# DA1470x register map
Vendor: Dialog; Series: DA1470x; File version: 1.2
CPU: CM33 r0p2, little endian, MPU, FPU, DSP, VTOR, 4 interrupt priority bits
Registers are 32-bit, read-write, reset 0x0 unless marked. A register's access mark holds for its fields unless they carry their own. Offsets are from the block's base; [hi:lo] are bit positions.

## EMMC (part 2 of 3) — EMMC registers
Base 0x30058000
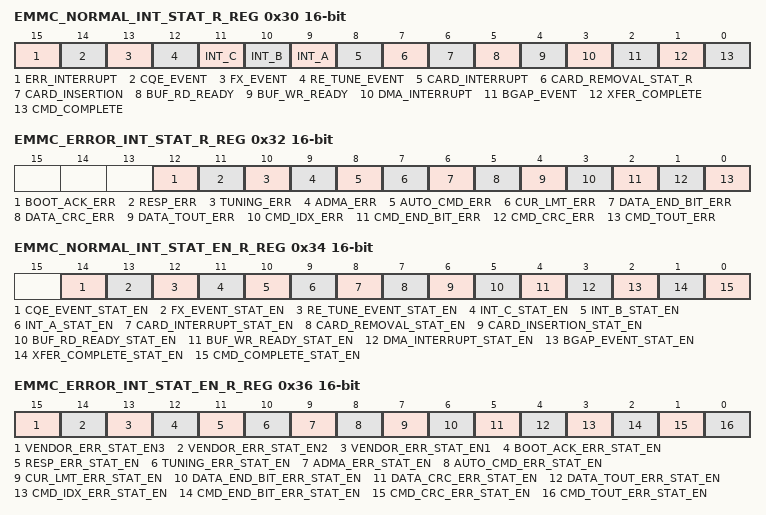
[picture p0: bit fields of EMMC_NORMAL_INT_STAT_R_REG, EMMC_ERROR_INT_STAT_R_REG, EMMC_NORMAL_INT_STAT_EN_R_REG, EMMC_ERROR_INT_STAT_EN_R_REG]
0x30 EMMC_NORMAL_INT_STAT_R_REG 16-bit — This register reflects the status of the Normal Interrupt. This register is applicable for an SD/eMMC/UHS-II mode.
  [15] ERR_INTERRUPT ro — Error Interrupt. If any of the bits in the Error Interrupt Status register are set, then this bit is set. Values: 0x0 (FALSE): No Error 0x1 (TRUE): Error
  [14] CQE_EVENT — Command Queuing Event This status is set if Command Queuing/Crypto related event has occurred in eMMC/SD mode. Read CQHCI's CQIS/CRNQIS register for more details. Values: 0x0 (FALSE): No Event 0x1 (TRUE): Command Queuing Event is detected
  [13] FX_EVENT ro — FX Event. This status is set when R[14] of response register is set to 1 and Response Type R1/R5 is set to 0 in Transfer Mode register. This interrupt is used with response check function. Values: 0x0 (FALSE): No Event 0x1 (TRUE): FX Event is detected
  [12] RE_TUNE_EVENT ro — Re-tuning Event. This bit is set if the Re-Tuning Request changes from 0 to 1. Re-Tuning request is not supported.
  [11] INT_C ro — INT_C (Embedded). This bit is set if INT_C is enabled and if INT_C# pin is in low level. The INT_C# pin is not supported.
  [10] INT_B ro — INT_B (Embedded). This bit is set if INT_B is enabled and if INT_B# pin is in low level. The INT_B# pin is not supported.
  [9] INT_A ro — INT_A (Embedded). This bit is set if INT_A is enabled and if INT_A# pin is in low level. The INT_A# pin is not supported.
  [8] CARD_INTERRUPT ro — Card Interrupt. This bit reflects the synchronized value of: - DAT[1] Interrupt Input for SD Mode - DAT[2] Interrupt Input for UHS-II Mode Values: 0x0 (FALSE): No Card Interrupt 0x1 (TRUE): Generate Card Interrupt
  [7] CARD_REMOVAL_STAT_R — Card Removal. This bit is set if the Card Inserted in the Present State register changes from 1 to 0. Values: 0x0 (FALSE): Card state stable or Debouncing 0x1 (TRUE): Card Removed
  [6] CARD_INSERTION — Card Insertion This bit is set if the Card Inserted in the Present State register changes from 0 to 1. Values: 0x0 (FALSE): Card state stable or Debouncing 0x1 (TRUE): Card Inserted
  [5] BUF_RD_READY — Buffer Read Ready. This bit is set if the Buffer Read Enable changes from 0 to 1. Values: 0x0 (FALSE): Not ready to read buffer 0x1 (TRUE): Ready to read buffer
  [4] BUF_WR_READY — Buffer Write Ready. This bit is set if the Buffer Write Enable changes from 0 to 1. Values: 0x0 (FALSE): Not ready to write buffer 0x1 (TRUE): Ready to write buffer
  [3] DMA_INTERRUPT — DMA Interrupt. This bit is set if the Host Controller detects the SDMA Buffer Boundary during transfer. In case of ADMA, by setting the Int field in the descriptor table, the Host controller generates this interrupt. This interrupt is not generated after a Transfer Complete. Values: 0x0 (FALSE): No DMA Interrupt 0x1 (TRUE): DMA Interrupt is generated
  [2] BGAP_EVENT — Block Gap Event. This bit is set when both read/write transaction is stopped at block gap due to a Stop at Block Gap Request. Values: 0x0 (FALSE): No Block Gap Event 0x1 (TRUE): Transaction stopped at block gap
  [1] XFER_COMPLETE — Transfer Complete. This bit is set when a read/write transfer and a command with status busy is completed. Values: 0x0 (FALSE): Not complete 0x1 (TRUE): Command execution is completed
  [0] CMD_COMPLETE — Command Complete. In an SD/eMMC Mode, this bit is set when the end bit of a response except for Auto CMD12 and Auto CMD23. This interrupt is not generated when the Response Interrupt Disable in Transfer Mode Register is set to 1. Values: 0x0 (FALSE): No command complete 0x1 (TRUE): Command Complete
0x32 EMMC_ERROR_INT_STAT_R_REG 16-bit — This register enables an interrupt when the Error Interrupt Status Enable is enabled and at least one of the statuses is set to
  [12] BOOT_ACK_ERR — Boot Acknowledgement Error. This bit is set when there is a timeout for boot acknowledgement or when detecting boot ack status having a value other than 010. This is applicable only when boot acknowledgement is expected in eMMC mode. Values: 0x0 (FALSE): No error 0x1 (TRUE): Error
  [11] RESP_ERR — Response Error. Host Controller Version 4.00 supports response error check function to avoid overhead of response error check by Host Driver during DMA execution. If Response Error Check Enable is set to 1 in the Transfer Mode register, Host Controller Checks R1 or R5 response. If an error is detected in a response, this bit is set to 1.This is applicable in SD/eMMC mode. Values: 0x0 (FALSE): No error 0x1 (TRUE): Error
  [10] TUNING_ERR — Tuning Error. This bit is set when an unrecoverable error is detected in a tuning circuit except during the tuning procedure (occurrence of an error during tuning procedure is indicated by Sampling Clock Select in the Host Control 2 register). By detecting Tuning Error, Host Driver needs to abort a command executing and perform tuning. To reset tuning circuit, Sampling Clock Select is set to 0 before executing tuning procedure. The Tuning Error is higher priority than the other error interrupts generated during data transfer. By detecting Tuning Error, the Host Driver must discard data transferred by a current read/write command and retry data transfer after the Host Controller retrieved from the tuning circuit error. This is applicable in SD/eMMC mode. Values: 0x0 (FALSE): No error 0x1 (TRUE): Error
  [9] ADMA_ERR — ADMA Error. This bit is set when the Host Controller detects error during ADMA-based data transfer. The error could be due to following reasons: - Error response received from System bus (Master I/F) - ADMA3,ADMA2 Descriptors invalid - CQE Task or Transfer descriptors invalid When the error occurs, the state of the ADMA is saved in the ADMA Error Status register. In eMMC CQE mode: The Host Controller generates this Interrupt when it detects an invalid descriptor data (Valid=0) at the ST_FDS state. ADMA Error State in the ADMA Error Status indicates that an error has occurred in ST_FDS state. The Host Driver may find that Valid bit is not set at the error descriptor. Values: 0x0 (FALSE): No error 0x1 (TRUE): Error
  [8] AUTO_CMD_ERR — Auto CMD Error. This error status is used by Auto CMD12 and Auto CMD23 in SD/eMMC mode. This bit is set when detecting that any of the bits D00 to D05 in Auto CMD Error Status register has changed from 0 to 1. D07 is effective in case of Auto CMD12. Auto CMD Error Status register is valid while this bit is set to 1 and may be cleared by clearing of this bit. Values: 0x0 (FALSE): No error 0x1 (TRUE): Error
  [7] CUR_LMT_ERR — Current Limit Error. By setting the SD Bus Power bit in the Power Control register, the Host Controller is requested to supply power for the SD Bus. If the Host Controller supports the Current Limit function, it can be protected from an illegal card by stopping power supply to the card in which case this bit indicates a failure status. A reading of 1 for this bit means that the Host Controller is not supplying power to the SD card due to some failure. A reading of 0 for this bit means that the Host Controller is supplying power and no error has occurred. The Host Controller may require some sampling time to detect the current limit. DWC_mshc Host Controller does not support this function, this bit is always set to 0. Values: 0x0 (FALSE): No error 0x1 (TRUE): Power Fail
  [6] DATA_END_BIT_ERR — Data End Bit Error. This error occurs in SD/eMMC mode either when detecting 0 at the end bit position of read data that uses the DAT line or at the end bit position of the CRC status. Values: 0x0 (FALSE): No error 0x1 (TRUE): Error
  [5] DATA_CRC_ERR — Data CRC Error. This error occurs in SD/eMMC mode when detecting CRC error when transferring read data which uses the DAT line, when detecting the Write CRC status having a value of other than 010 or when write CRC status timeout. Values: 0x0 (FALSE): No error 0x1 (TRUE): Error
  [4] DATA_TOUT_ERR — Data Timeout Error. This bit is set in SD/eMMC mode when detecting one of the following timeout conditions: - Busy timeout for R1b, R5b type - Busy timeout after Write CRC status - Write CRC Status timeout - Read Data timeout Values: 0x0 (FALSE): No error 0x1 (TRUE): Time out
  [3] CMD_IDX_ERR — Command Index Error. This bit is set if a Command Index error occurs in the command respons in SD/eMMC mode. Values: 0x0 (FALSE): No error 0x1 (TRUE): Error
  [2] CMD_END_BIT_ERR — Command End Bit Error. This bit is set when detecting that the end bit of a command response is 0 in SD/eMMC mode. Values: 0x0 (FALSE): No error 0x1 (TRUE): End Bit error generated
  [1] CMD_CRC_ERR — Command CRC Error. Command CRC Error is generated in SD/eMMC mode for following two cases. - If a response is returned and the Command Timeout Error is set to 0 (indicating no timeout), this bit is set to 1 when detecting a CRC error in the command response. - The Host Controller detects a CMD line conflict by monitoring the CMD line when a command is issued. If the Host Controller drives the CMD line to 1 level, but detects 0 level on the CMD line at the next SD clock edge, then the Host Controller aborts the command (stop driving CMD line) and set this bit to 1. The Command Timeout Error is also set to 1 to distinguish a CMD line conflict. Values: 0x0 (FALSE): No error 0x1 (TRUE): CRC error generated
  [0] CMD_TOUT_ERR — Command Timeout Error. In SD/eMMC Mode,this bit is set only if no response is returned within 64 SD clock cycles from the end bit of the command. If the Host Controller detects a CMD line conflict, along with Command CRC Error bit, this bit is set to 1, without waiting for 64 SD/eMMC card clock cycles. Values: 0x0 (FALSE): No error 0x1 (TRUE): Time out
0x34 EMMC_NORMAL_INT_STAT_EN_R_REG 16-bit — This register enables the Interrupt Status for Normal Interrupt Status register (NORMAL_INT_STAT_R) when NORMAL_INT_STAT_R is s
  [14] CQE_EVENT_STAT_EN — CQE Event Status Enable Values: 0x0 (FALSE): Masked 0x1 (TRUE): Enabled
  [13] FX_EVENT_STAT_EN — FX Event Status Enable This bit is added from Version 4.10. Values: 0x0 (FALSE): Masked 0x1 (TRUE): Enabled
  [12] RE_TUNE_EVENT_STAT_EN — Re-Tuning Event (UHS-I only) Status Enable Values: 0x0 (FALSE): Masked 0x1 (TRUE): Enabled
  [11] INT_C_STAT_EN — INT_C (Embedded) Status Enable If this bit is set to 0, the Host Controller clears the interrupt request to the System. The Host Driver may clear this bit before servicing the INT_C and may set this bit again after all interrupt requests to INT_C pin are cleared to prevent inadvertent interrupts. Values: 0x0 (FALSE): Masked 0x1 (TRUE): Enabled
  [10] INT_B_STAT_EN — INT_B (Embedded) Status Enable If this bit is set to 0, the Host Controller clears the interrupt request to the System. The Host Driver may clear this bit before servicing the INT_B and may set this bit again after all interrupt requests to INT_B pin are cleared to prevent inadvertent interrupts. Values: 0x0 (FALSE): Masked 0x1 (TRUE): Enabled
  [9] INT_A_STAT_EN — INT_A (Embedded) Status Enable If this bit is set to 0, the Host Controller clears the interrupt request to the System. The Host Driver may clear this bit before servicing the INT_A and may set this bit again after all interrupt requests to INT_A pin are cleared to prevent inadvertent interrupts. Values: 0x0 (FALSE): Masked 0x1 (TRUE): Enabled
  [8] CARD_INTERRUPT_STAT_EN — Card Interrupt Status Enable If this bit is set to 0, the Host Controller clears the interrupt request to the System. The Card Interrupt detection is stopped when this bit is cleared and restarted when this bit is set to 1. The Host Driver may clear the Card Interrupt Status Enable before servicing the Card Interrupt and may set this bit again after all interrupt requests from the card are cleared to prevent inadvertent interrupts. By setting this bit to 0, interrupt input must be masked by implementation so that the interrupt input is not affected by external signal in any state (for example, floating). Values: 0x0 (FALSE): Masked 0x1 (TRUE): Enabled
  [7] CARD_REMOVAL_STAT_EN — Card Removal Status Enable Values: 0x0 (FALSE): Masked 0x1 (TRUE): Enabled
  [6] CARD_INSERTION_STAT_EN — Card Insertion Status Enable Values: 0x0 (FALSE): Masked 0x1 (TRUE): Enabled
  [5] BUF_RD_READY_STAT_EN — Buffer Read Ready Status Enable Values: 0x0 (FALSE): Masked 0x1 (TRUE): Enabled
  [4] BUF_WR_READY_STAT_EN — Buffer Write Ready Status Enable Values: 0x0 (FALSE): Masked 0x1 (TRUE): Enabled
  [3] DMA_INTERRUPT_STAT_EN — DMA Interrupt Status Enable Values: 0x0 (FALSE): Masked 0x1 (TRUE): Enabled
  [2] BGAP_EVENT_STAT_EN — Block Gap Event Status Enable Values: 0x0 (FALSE): Masked 0x1 (TRUE): Enabled
  [1] XFER_COMPLETE_STAT_EN — Transfer Complete Status Enable Values: 0x0 (FALSE): Masked 0x1 (TRUE): Enabled
  [0] CMD_COMPLETE_STAT_EN — Command Complete Status Enable Values: 0x0 (FALSE): Masked 0x1 (TRUE): Enabled
0x36 EMMC_ERROR_INT_STAT_EN_R_REG 16-bit — This register sets the Interrupt Status for Error Interrupt Status register (ERROR_INT_STAT_R), when ERROR_INT_STAT_EN_R is set
  [15] VENDOR_ERR_STAT_EN3 — The 15th bit of Error Interrupt Status Enable register is reserved. Values: 0x0 (FALSE): Masked 0x1 (TRUE): Enabled
  [14] VENDOR_ERR_STAT_EN2 — The 14th bit of Error Interrupt Status Enable register is reserved. Values: 0x0 (FALSE): Masked 0x1 (TRUE): Enabled
  [13] VENDOR_ERR_STAT_EN1 — The 13th bit of Error Interrupt Status Enable register is reserved. Values: 0x0 (FALSE): Masked 0x1 (TRUE): Enabled
  [12] BOOT_ACK_ERR_STAT_EN — Boot Acknowledgment Error (eMMC Mode only) Setting this bit to 1 enables setting of Boot Acknowledgment Error in Error Interrupt Status register (ERROR_INT_STAT_R). Values: 0x0 (FALSE): Masked 0x1 (TRUE): Enabled
  [11] RESP_ERR_STAT_EN — Response Error Status Enable (SD Mode only) Values: 0x0 (FALSE): Masked 0x1 (TRUE): Enabled
  [10] TUNING_ERR_STAT_EN — Tuning Error Status Enable (UHS-I Mode only) Values: 0x0 (FALSE): Masked 0x1 (TRUE): Enabled
  [9] ADMA_ERR_STAT_EN — ADMA Error Status Enable Values: 0x0 (FALSE): Masked 0x1 (TRUE): Enabled
  [8] AUTO_CMD_ERR_STAT_EN — Auto CMD Error Status Enable (SD/eMMC Mode only). Values: 0x0 (FALSE): Masked 0x1 (TRUE): Enabled
  [7] CUR_LMT_ERR_STAT_EN — Current Limit Error Status Enable Values: 0x0 (FALSE): Masked 0x1 (TRUE): Enabled
  [6] DATA_END_BIT_ERR_STAT_EN — Data End Bit Error Status Enable (SD/eMMC Mode only). Values: 0x0 (FALSE): Masked 0x1 (TRUE): Enabled
  [5] DATA_CRC_ERR_STAT_EN — Data CRC Error Status Enable (SD/eMMC Mode only) Values: 0x0 (FALSE): Masked 0x1 (TRUE): Enabled
  [4] DATA_TOUT_ERR_STAT_EN — Data Timeout Error Status Enable (SD/eMMC Mode only) Values: 0x0 (FALSE): Masked 0x1 (TRUE): Enabled
  [3] CMD_IDX_ERR_STAT_EN — Command Index Error Status Enable (SD/eMMC Mode only) Values: 0x0 (FALSE): Masked 0x1 (TRUE): Enabled
  [2] CMD_END_BIT_ERR_STAT_EN — Command End Bit Error Status Enable (SD/eMMC Mode only) Values: 0x0 (FALSE): Masked 0x1 (TRUE): Enabled
  [1] CMD_CRC_ERR_STAT_EN — Command CRC Error Status Enable (SD/eMMC Mode only) Values: 0x0 (FALSE): Masked 0x1 (TRUE): Enabled
  [0] CMD_TOUT_ERR_STAT_EN — Command Timeout Error Status Enable (SD/eMMC Mode only). Values: 0x0 (FALSE): Masked 0x1 (TRUE): Enabled
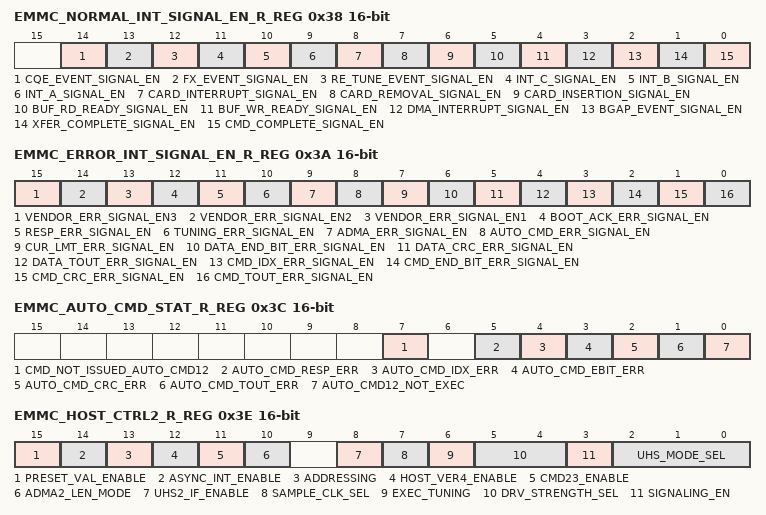
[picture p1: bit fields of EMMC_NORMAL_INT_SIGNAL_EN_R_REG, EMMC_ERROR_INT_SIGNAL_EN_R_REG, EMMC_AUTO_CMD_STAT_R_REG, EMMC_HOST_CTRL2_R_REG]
0x38 EMMC_NORMAL_INT_SIGNAL_EN_R_REG 16-bit — This register is used to select the interrupt status that is indicated to the Host System as the interrupt. All these status bi
  [14] CQE_EVENT_SIGNAL_EN — Command Queuing Engine Event Signal Enable Values: 0x0 (FALSE): Masked 0x1 (TRUE): Enabled
  [13] FX_EVENT_SIGNAL_EN — FX Event Signal Enable Values: 0x0 (FALSE): Masked 0x1 (TRUE): Enabled
  [12] RE_TUNE_EVENT_SIGNAL_EN — Re-Tuning Event (UHS-I only) Signal Enable. Values: 0x0 (FALSE): Masked 0x1 (TRUE): Enabled
  [11] INT_C_SIGNAL_EN — INT_C (Embedded) Signal Enable Values: 0x0 (FALSE): Masked 0x1 (TRUE): Enabled
  [10] INT_B_SIGNAL_EN — INT_B (Embedded) Signal Enable Values: 0x0 (FALSE): Masked 0x1 (TRUE): Enabled
  [9] INT_A_SIGNAL_EN — INT_A (Embedded) Signal Enable Values: 0x0 (FALSE): Masked 0x1 (TRUE): Enabled
  [8] CARD_INTERRUPT_SIGNAL_EN — Card Interrupt Signal Enable Values: 0x0 (FALSE): Masked 0x1 (TRUE): Enabled
  [7] CARD_REMOVAL_SIGNAL_EN — Card Removal Signal Enable Values: 0x0 (FALSE): Masked 0x1 (TRUE): Enabled
  [6] CARD_INSERTION_SIGNAL_EN — Card Insertion Signal Enable Values: 0x0 (FALSE): Masked 0x1 (TRUE): Enabled
  [5] BUF_RD_READY_SIGNAL_EN — Buffer Read Ready Signal Enable Values: 0x0 (FALSE): Masked 0x1 (TRUE): Enabled
  [4] BUF_WR_READY_SIGNAL_EN — Buffer Write Ready Signal Enable Values: 0x0 (FALSE): Masked 0x1 (TRUE): Enabled
  [3] DMA_INTERRUPT_SIGNAL_EN — DMA Interrupt Signal Enable Values: 0x0 (FALSE): Masked 0x1 (TRUE): Enabled
  [2] BGAP_EVENT_SIGNAL_EN — Block Gap Event Signal Enable Values: 0x0 (FALSE): Masked 0x1 (TRUE): Enabled
  [1] XFER_COMPLETE_SIGNAL_EN — Transfer Complete Signal Enable Values: 0x0 (FALSE): Masked 0x1 (TRUE): Enabled
  [0] CMD_COMPLETE_SIGNAL_EN — Command Complete Signal Enable Values: 0x0 (FALSE): Masked 0x1 (TRUE): Enabled
0x3A EMMC_ERROR_INT_SIGNAL_EN_R_REG 16-bit — This register is used to select the interrupt status that is notified to the Host System as an interrupt. All these status bits
  [15] VENDOR_ERR_SIGNAL_EN3 — The 16th bit of Error Interrupt Signal Enable is reserved. Values: 0x0 (FALSE): Masked 0x1 (TRUE): Enabled
  [14] VENDOR_ERR_SIGNAL_EN2 — The 15th bit of Error Interrupt Signal Enable is reserved. Values: 0x0 (FALSE): Masked 0x1 (TRUE): Enabled
  [13] VENDOR_ERR_SIGNAL_EN1 — The 14th bit of Error Interrupt Signal Enable is reserved. Values: 0x0 (FALSE): Masked 0x1 (TRUE): Enabled
  [12] BOOT_ACK_ERR_SIGNAL_EN — Boot Acknowledgment Error (eMMC Mode only). Setting this bit to 1 enables generating interrupt signal when Boot Acknowledgement Error in Error Interrupt Status register is set. Values: 0x0 (FALSE): Masked 0x1 (TRUE): Enabled
  [11] RESP_ERR_SIGNAL_EN — Response Error Signal Enable (SD Mode only) Values: 0x0 (FALSE): Masked 0x1 (TRUE): Enabled
  [10] TUNING_ERR_SIGNAL_EN — Tuning Error Signal Enable (UHS-I Mode only) Values: 0x0 (FALSE): Masked 0x1 (TRUE): Enabled
  [9] ADMA_ERR_SIGNAL_EN — ADMA Error Signal Enable Values: 0x0 (FALSE): Masked 0x1 (TRUE): Enabled
  [8] AUTO_CMD_ERR_SIGNAL_EN — Auto CMD Error Signal Enable (SD/eMMC Mode only) Values: 0x0 (FALSE): Masked 0x1 (TRUE): Enabled
  [7] CUR_LMT_ERR_SIGNAL_EN — Current Limit Error Signal Enable Values: 0x0 (FALSE): Masked 0x1 (TRUE): Enabled
  [6] DATA_END_BIT_ERR_SIGNAL_EN — Data End Bit Error Signal Enable (SD/eMMC Mode only) Values: 0x0 (FALSE): Masked 0x1 (TRUE): Enabled
  [5] DATA_CRC_ERR_SIGNAL_EN — Data CRC Error Signal Enable (SD/eMMC Mode only) Values: 0x0 (FALSE): Masked 0x1 (TRUE): Enabled
  [4] DATA_TOUT_ERR_SIGNAL_EN — Data Timeout Error Signal Enable (SD/eMMC Mode only) Values: 0x0 (FALSE): Masked 0x1 (TRUE): Enabled
  [3] CMD_IDX_ERR_SIGNAL_EN — Command Index Error Signal Enable (SD/eMMC Mode only) Values: 0x0 (FALSE): Masked 0x1 (TRUE): Enabled
  [2] CMD_END_BIT_ERR_SIGNAL_EN — Command End Bit Error Signal Enable (SD/eMMC Mode only) Values: 0x0 (FALSE): Masked 0x1 (TRUE): Enabled
  [1] CMD_CRC_ERR_SIGNAL_EN — Command CRC Error Signal Enable (SD/eMMC Mode only) Values: 0x0 (FALSE): Masked 0x1 (TRUE): Enabled
  [0] CMD_TOUT_ERR_SIGNAL_EN — Command Timeout Error Signal Enable (SD/eMMC Mode only) Values: 0x0 (FALSE): Masked 0x1 (TRUE): Enabled
0x3C EMMC_AUTO_CMD_STAT_R_REG 16-bit — This register is used to indicate the CMD12 response error of Auto CMD12, and the CMD23 response error of Auto CMD23. The Host
  [7] CMD_NOT_ISSUED_AUTO_CMD12 ro — Command Not Issued By Auto CMD12 Error If this bit is set to 1, CMD_wo_DAT is not executed due to an Auto CMD12 Error (D04-D01) in this register. This bit is set to 0 when Auto CMD Error is generated by Auto CMD23. Values: 0x1 (TRUE): Not Issued 0x0 (FALSE): No Error
  [5] AUTO_CMD_RESP_ERR ro — Auto CMD Response Error This bit is set when Response Error Check Enable in the Transfer Mode register is set to 1 and an error is detected in R1 response of either Auto CMD12 or CMD13. This status is ignored if any bit between D00 to D04 is set to 1. Values: 0x1 (TRUE): Error 0x0 (FALSE): No Error
  [4] AUTO_CMD_IDX_ERR ro — Auto CMD Index Error This bit is set if the command index error occurs in response to a command. Values: 0x1 (TRUE): Error 0x0 (FALSE): No Error
  [3] AUTO_CMD_EBIT_ERR ro — Auto CMD End Bit Error This bit is set when detecting that the end bit of command response is 0. Values: 0x1 (TRUE): End Bit Error Generated 0x0 (FALSE): No Error
  [2] AUTO_CMD_CRC_ERR ro — Auto CMD CRC Error This bit is set when detecting a CRC error in the command response. Values: 0x1 (TRUE): CRC Error Generated 0x0 (FALSE): No Error
  [1] AUTO_CMD_TOUT_ERR ro — Auto CMD Timeout Error This bit is set if no response is returned with 64 SDCLK cycles from the end bit of the command. If this bit is set to 1, error status bits (D04-D01) are meaningless. Values: 0x1 (TRUE): Time out 0x0 (FALSE): No Error
  [0] AUTO_CMD12_NOT_EXEC ro — Auto CMD12 Not Executed If multiple memory block data transfer is not started due to a command error, this bit is not set because it is not necessary to issue an Auto CMD12. Setting this bit to 1 means that the Host Controller cannot issue Auto CMD12 to stop multiple memory block data transfer, due to some error. If this bit is set to 1, error status bits (D04-D01) is meaningless. This bit is set to 0 when Auto CMD Error is generated by Auto CMD23. Values: 0x1 (TRUE): Not Executed 0x0 (FALSE): Executed
0x3E EMMC_HOST_CTRL2_R_REG 16-bit — This register is used to control how the Host Controller operates. This register is applicable for an SD/eMMC/UHS-II mode.
  [15] PRESET_VAL_ENABLE — Preset Value Enable This bit enables automatic selection of SDCLK frequency and Driver strength Preset Value registers. When Preset Value Enable is set, SDCLK frequency generation (Frequency Select and Clock Generator Select) and the driver strength selection are performed by the controller. These values are selected from set of Preset Value registers based on selected speed mode. Note: For more information, see the FAQ on Preset Register in the DWC_mshc Databook. Values: 0x0 (FALSE): SDCLK and Driver Strength are controlled by Host Driver 0x1 (TRUE): Automatic Selection by Preset Value are Enabled
  [14] ASYNC_INT_ENABLE — Asynchronous Interrupt Enable This bit can be set if a card supports asynchronous interrupts and Asynchronous Interrupt Support is set to 1 in the Capabilities register. Values: 0x0 (FALSE): Disabled 0x1 (TRUE): Enabled
  [13] ADDRESSING — 64-bit Addressing This bit is effective when Host Version 4 Enable is set to 1. Values: 0x0 (FALSE): 32 bits addressing 0x1 (TRUE): 64 bits addressing
  [12] HOST_VER4_ENABLE — Host Version 4 Enable This bit selects either Version 3.00 compatible mode or Version 4 mode. Functions of following fields are modified for Host Version 4 mode: - SDMA Address: SDMA uses ADMA System Address (05Fh-058h) instead of SDMA System Address register (003h-000h) - ADMA2/ADMA3 selection: ADMA3 is selected by DMA select in Host Control 1 register - 64-bit ADMA Descriptor Size: 128-bit descriptor is used instead of 96-bit descriptor when 64-bit Addressing is set to 1 - Selection of 32-bit/64-bit System Addressing: Either 32-bit or 64-bit system addressing is selected by 64-bit Addressing bit in this register - 32-bit Block Count: SDMA System Address register (003h-000h) is modified to 32-bit Block Count register Note: It is recommended not to program ADMA3 Integrated Descriptor Address registers, UHS-II registers and Command Queuing registers (if applicable) while operating in Host version less than 4 mode (Host Version 4 Enable = 0). Values: 0x0 (FALSE): Version 3.00 compatible mode 0x1 (TRUE): Version 4 mode
  [11] CMD23_ENABLE — CMD23 Enable If the card supports CMD23, this bit is set to 1. This bit is used to select Auto CMD23 or Auto CMD12 for ADMA3 data transfer. Values: 0x0 (FALSE): Auto CMD23 is disabled 0x1 (TRUE): Auto CMD23 is enabled
  [10] ADMA2_LEN_MODE — ADMA2 Length Mode This bit selects ADMA2 Length mode to be either 16-bit or 26-bit. Values: 0x0 (FALSE): 16-bit Data Length Mode 0x1 (TRUE): 26-bit Data Length Mode
  [8] UHS2_IF_ENABLE — UHS-II Interface Enable This bit is used to enable the UHS-II Interface. The value is reflected on the uhs2_if_en pin. Values: 0x0 (FALSE): SD/eMMC Interface Enabled 0x1 (TRUE): UHS-II Interface Enabled
  [7] SAMPLE_CLK_SEL — Sampling Clock Select This bit is used by the Host Controller to select the sampling clock in SD/eMMC mode to receive CMD and DAT. This bit is set by the tuning procedure and is valid after the completion of tuning (when Execute Tuning is cleared). Setting this bit to 1 means that tuning is completed successfully and setting this bit to 0 means that tuning has failed. The value is reflected on the sample_cclk_sel pin. Values: 0x0 (FALSE): Fixed clock is used to sample data 0x1 (TRUE): Tuned clock is used to sample data
  [6] EXEC_TUNING — Execute Tuning This bit is set to 1 to start the tuning procedure in UHS-I/eMMC speed modes and this bit is automatically cleared when tuning procedure is completed. Values: 0x0 (FALSE): Not Tuned or Tuning completed 0x1 (TRUE): Execute Tuning
  [5:4] DRV_STRENGTH_SEL — Driver Strength Select This bit is used to select the Host Controller output driver in 1.8V signaling UHS-I/eMMC speed modes. The bit depends on setting of Preset Value Enable. The value is reflected on the uhs1_drv_sth pin. Values: 0x0 (TYPEB): Driver TYPEB is selected 0x1 (TYPEA): Driver TYPEA is selected 0x2 (TYPEC): Driver TYPEC is selected 0x3 (TYPED): Driver TYPED is selected
  [3] SIGNALING_EN — 1.8V Signaling Enable This bit controls voltage regulator for I/O cell in UHS-I/eMMC speed modes. Setting this bit from 0 to 1 starts changing the signal voltage from 3.3V to 1.8V. Host Controller clears this bit if switching to 1.8 signaling fails. The value is reflected on the uhs1_swvolt_en pin. Note: This bit must be set for all UHS-I speed modes (SDR12/SDR25/SDR50/SDR104/DDR50). Values: 0x0 (V_3_3): 3.3V Signalling 0x1 (V_1_8): 1.8V Signalling
  [2:0] UHS_MODE_SEL — UHS Mode/eMMC Speed Mode Select These bits are used to select UHS mode in the SD mode of operation. In eMMC mode, these bits are used to select eMMC Speed mode. UHS Mode (SD/UHS-II mode only): - 0x0: SDR12 - 0x1: SDR25 - 0x2: SDR50 - 0x3: SDR104 - 0x4: DDR50 - 0x5: Reserved - 0x6: Reserved - 0x7: UHS-II eMMC Speed Mode (eMMC mode only): - 0x0: Legacy - 0x1: High Speed SDR - 0x2: Reserved - 0x3: HS200 - 0x4: High Speed DDR - 0x5: Reserved - 0x6: Reserved - 0x7: HS400 Values: 0x0 (SDR12): SDR12/Legacy 0x1 (SDR25): SDR25/High Speed SDR 0x2 (SDR50): SDR50 0x3 (SDR104): SDR104/HS200 0x4 (DDR50): DDR50/High Speed DDR 0x5 (RSVD5): Reserved 0x6 (RSVD6): Reserved 0x7 (UHS2): UHS-II/HS400
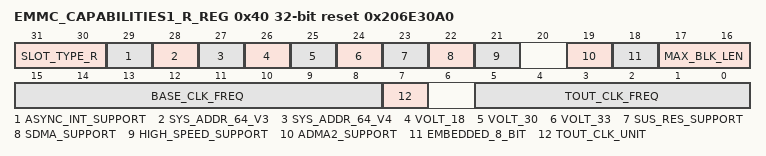
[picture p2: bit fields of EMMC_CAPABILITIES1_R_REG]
0x40 EMMC_CAPABILITIES1_R_REG reset 0x206E30A0 (reset mask 0x7FFFFFFF) — This register provides the Host Driver with information specific to the Host Controller implementation. The host controller may
  [31:30] SLOT_TYPE_R ro — Slot Type These bits indicate usage of a slot by a specific Host System. Values: 0x0 (REMOVABLE_SLOT): Removable Card Slot 0x1 (EMBEDDED_SLOT): Embedded Slot for one Device 0x2 (SHARED_SLOT): Shared Bus Slot (SD mode) 0x3 (UHS2_EMBEDDED_SLOT): UHS-II MultipleEmbedded Devices
  [29] ASYNC_INT_SUPPORT ro — Asynchronous Interrupt Support (SD Mode only) Values: 0x0 (FALSE): Asynchronous Interrupt Not Supported 0x1 (TRUE): Asynchronous Interrupt Supported
  [28] SYS_ADDR_64_V3 ro — 64-bit System Address Support for V3 This bit sets the Host controller to support 64-bit System Addressing of V3 mode. SDMA cannot be used in 64-bit Addressing in Version 3 Mode. If this bit is set to 1, 64-bit ADMA2 with using 96-bit Descriptor can be enabled by setting Host Version 4 Enable (HOST_VER4_ENABLE = 0) and DMA select (DMA_SEL = 11b). Values: 0x0 (FALSE): 64-bit System Address for V3 is Not Supported 0x1 (TRUE): 64-bit System Address for V3 is Supported
  [27] SYS_ADDR_64_V4 ro — 64-bit System Address Support for V4 This bit sets the Host Controller to support 64-bit System Addressing of V4 mode. When this bit is set to 1, full or part of 64-bit address must be used to decode the Host Controller Registers so that Host Controller Registers can be placed above system memory area. 64-bit address decode of Host Controller registers is effective regardless of setting to 64-bit Addressing in Host Control 2. If this bit is set to 1, 64-bit DMA Addressing for version 4 is enabled by setting Host Version 4 Enable (HOST_VER4_ENABLE = 1) and by setting 64-bit Addressing (ADDRESSING =1) in the Host Control 2 register. SDMA can be used and ADMA2 uses 128-bit Descriptor. Values: 0x0 (FALSE): 64-bit System Address for V4 is Not Supported 0x1 (TRUE): 64-bit System Address for V4 is Supported
  [26] VOLT_18 ro — Voltage Support for 1.8V Values: 0x0 (FALSE): 1.8V Not Supported 0x1 (TRUE): 1.8V Supported
  [25] VOLT_30 ro — Voltage Support for SD 3.0V or Embedded 1.2V Values: 0x0 (FALSE): SD 3.0V or Embedded 1.2V Not Supported 0x1 (TRUE): SD 3.0V or Embedded Supported
  [24] VOLT_33 ro — Voltage Support for 3.3V Values: 0x0 (FALSE): 3.3V Not Supported 0x1 (TRUE): 3.3V Supported
  [23] SUS_RES_SUPPORT ro — Suspense/Resume Support This bit indicates whether the Host Controller supports Suspend/Resume functionality. If this bit is 0, the Host Driver does not issue either Suspend or Resume commands because the Suspend and Resume mechanism is not supported. Values: 0x0 (FALSE): Not Supported 0x1 (TRUE): Supported
  [22] SDMA_SUPPORT ro — SDMA Support This bit indicates whether the Host Controller is capable of using SDMA to transfer data between the system memory and the Host Controller directly. Values: 0x0 (FALSE): SDMA not Supported 0x1 (TRUE): SDMA Supported
  [21] HIGH_SPEED_SUPPORT ro — High Speed Support This bit indicates whether the Host Controller and the Host System supports High Speed mode and they can supply the SD Clock frequency from 25 MHz to 50 MHz. Values: 0x0 (FALSE): High Speed not Supported 0x1 (TRUE): High Speed Supported
  [19] ADMA2_SUPPORT ro — ADMA2 Support This bit indicates whether the Host Controller is capable of using ADMA2. Values: 0x0 (FALSE): ADMA2 not Supported 0x1 (TRUE): ADMA2 Supported
  [18] EMBEDDED_8_BIT ro — 8-bit Support for Embedded Device This bit indicates whether the Host Controller is capable of using an 8-bit bus width mode. This bit is not effective when the Slot Type is set to 10b. Values: 0x0 (FALSE): 8-bit Bus Width not Supported 0x1 (TRUE): 8-bit Bus Width Supported
  [17:16] MAX_BLK_LEN ro — Maximum Block Length This bit indicates the maximum block size that the Host driver can read and write to the buffer in the Host Controller. The buffer transfers this block size without wait cycles. The transfer block length is always 512 bytes for the SD Memory irrespective of this bit Values: 0x0 (ZERO): 512 Byte 0x1 (ONE): 1024 Byte 0x2 (TWO): 2048 Byte 0x3 (THREE): Reserved
  [15:8] BASE_CLK_FREQ ro — Base Clock Frequency for SD clock These bits indicate the base (maximum) clock frequency for the SD Clock. The definition of these bits depend on the Host Controller Version. - 6-Bit Base Clock Frequency: This mode is supported by the Host Controller version 1.00 and 2.00. The upper 2 bits are not effective and are always 0. The unit values are 1 MHz. The supported clock range is 10 MHz to 63 MHz. -- 0x00 : Get information through another method -- 0x01 : 1 MHz -- 0x02 : 2 MHz -- ............. -- 0x3F : 63 MHz -- 0x40-0xFF : Not Supported - 8-Bit Base Clock Frequency: This mode is supported by the Host Controller version 3.00. The unit values are 1 MHz. The supported clock range is 10 MHz to 255 MHz. -- 0x00 : Get information through another method -- 0x01 : 1 MHz -- 0x02 : 2 MHz -- ............ -- 0xFF : 255 MHz If the frequency is 16.5 MHz, the larger value is set to 0001001b (17 MHz) because the Host Driver uses this value to calculate the clock divider value and it does not exceed the upper limit of the SD Clock frequency. If these bits are all 0, the Host system has to get information using a different method.
  [7] TOUT_CLK_UNIT ro — Timeout Clock Unit This bit shows the unit of base clock frequency used to detect Data TImeout Error. Values: 0x0 (KHZ): KHz 0x1 (MHZ): MHz
  [5:0] TOUT_CLK_FREQ ro — Timeout Clock Frequency This bit shows the base clock frequency used to detect Data Timeout Error. The Timeout Clock unit defines the unit of timeout clock frequency. It can be KHz or MHz. - 0x00 : Get information through another method - 0x01 : 1KHz / 1MHz - 0x02 : 2KHz / 2MHz - 0x03 : 3KHz / 3MHz - ........... - 0x3F : 63KHz / 63MHz
